# GD32F20x_CL register map
File version: 1.0
CPU: CM3 r2p1, little endian, no MPU, no FPU, 4 interrupt priority bits
Registers are 32-bit, read-write, reset 0x0 unless marked. A register's access mark holds for its fields unless they carry their own. Offsets are from the block's base; [hi:lo] are bit positions; {n}, {i} and the like mark numbered series.

## CAU — Cryptographic acceleration unit
Base 0x50060000
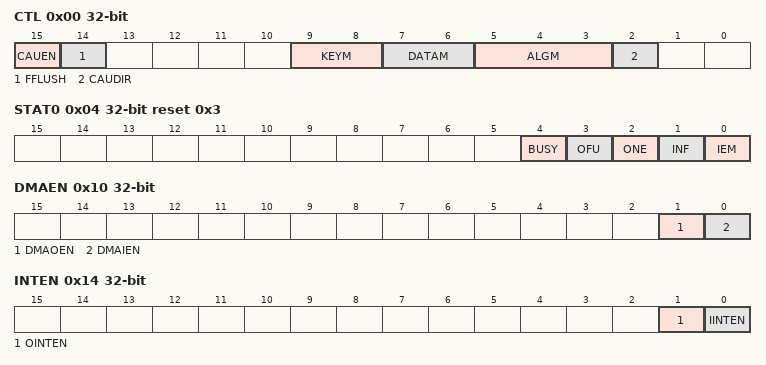
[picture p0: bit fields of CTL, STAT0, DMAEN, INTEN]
0x00 CTL access per field — CAU control register
  [15] CAUEN rw — Cryptographic module enable
  [14] FFLUSH wo — FIFO flush
  [9:8] KEYM rw — AES key size mode configuration
  [7:6] DATAM rw — Data swapping type mode configuration
  [5:3] ALGM rw — Encryption/decryption algorithm mode
  [2] CAUDIR rw — CAU direction
0x04 STAT0 ro reset 0x3 — CAU status register 0
  [4] BUSY — BUSY flag
  [3] OFU — OUT FIFO full flag
  [2] ONE — OUT FIFO not empty flag
  [1] INF — IN FIFO not full flag
  [0] IEM — IN FIFO empty flag
0x08 DI — CAU data input register
  [31:0] DI — Data input
0x0C DO ro — CAU data output register
  [31:0] DO — Data output
0x10 DMAEN — CAU DMA enable register
  [1] DMAOEN — Out FIFO DMA enable
  [0] DMAIEN — In FIFO DMA enable
0x14 INTEN — CAU interrupt enable register
  [1] OINTEN — Out FIFO interrupt enable
  [0] IINTEN — In FIFO interrupt enable
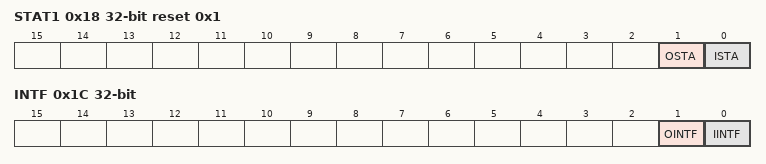
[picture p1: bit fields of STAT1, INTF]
0x18 STAT1 ro reset 0x1 — CAU interrupt status flag register 1
  [1] OSTA — Out FIFO interrupt flag
  [0] ISTA — In FIFO interrupt flag
0x1C INTF ro — CAU enable interrupt status flag register
  [1] OINTF — Out FIFO enabled interrupt flag
  [0] IINTF — In FIFO enabled interrupt flag
{0x20+8i} KEY{i}H wo (i=0..3) — CAU key register
  [31:0] KEY{i}H — Key for DES,TDES,AES
{0x24+8i} KEY{i}L wo (i=0..3) — CAU key register
  [31:0] KEY{i}L — Key for DES,TDES,AES
0x40 IV0H — CAU initialization register
  [31:0] IV0H — The initialization vector for DES,TDES,AES
0x44 IV0L — CAU initialization register
  [31:0] IV0L — The initialization vector for DES,TDES,AES
0x48 IV1H — CAU initialization register
  [31:0] IV1H — The initialization vector for DES,TDES,AES
0x4C IV1L — CAU initialization register
  [31:0] IV1L — The initialization vector for DES,TDES,AES

## CRC — CRC calculation unit
Base 0x40023000
0x00 DATA reset 0xFFFFFFFF
  [31:0] DATA — CRC calculation result bits
0x04 FDATA — Independent Data register
  [7:0] FDATA — Free Data Register bits
0x08 CTL wo — Control register
  [0] RST — Reset bit

## DAC — Digital to analog converter
Base 0x40007400
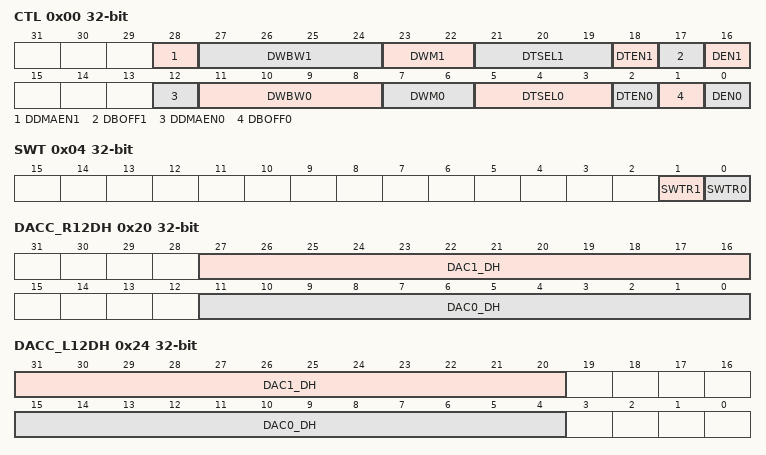
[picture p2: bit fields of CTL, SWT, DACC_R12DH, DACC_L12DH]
0x00 CTL — control register
  [28] DDMAEN1 — DAC1 DMA enable
  [27:24] DWBW1 — DAC1 noise wave bit width
  [23:22] DWM1 — DAC1 noise wave mode
  [21:19] DTSEL1 — DAC1 trigger selection
  [18] DTEN1 — DAC1 trigger enable
  [17] DBOFF1 — DAC1 output buffer turn off
  [16] DEN1 — DAC1 enable
  [12] DDMAEN0 — DAC0 DMA enable
  [11:8] DWBW0 — DAC0 noise wave bit width
  [7:6] DWM0 — DAC0 noise wave mode
  [5:3] DTSEL0 — DAC0 trigger selection
  [2] DTEN0 — DAC0 trigger enable
  [1] DBOFF0 — DAC0 output buffer turn off
  [0] DEN0 — DAC0 enable
0x04 SWT wo — software trigger register
  [1] SWTR1 — DAC1 software trigger
  [0] SWTR0 — DAC0 software trigger
0x08 DAC0_R12DH — DAC0 12-bit right-aligned data holding register
  [11:0] DAC0_DH — DAC0 12-bit right-aligned data
0x0C DAC0_L12DH — DAC0 12-bit left-aligned data holding register
  [15:4] DAC0_DH — DAC0 12-bit left-aligned data
0x10 DAC0_R8DH — DAC0 8-bit right aligned data holding register
  [7:0] DAC0_DH — DAC0 8-bit right-aligned data
0x14 DAC1_R12DH — DAC1 12-bit right-aligned data holding register
  [11:0] DAC1_DH — DAC1 12-bit right-aligned data
0x18 DAC1_L12DH — DAC1 12-bit left aligned data holding register
  [15:4] DAC1_DH — DAC1 12-bit left-aligned data
0x1C DAC1_R8DH — DAC1 8-bit right aligned data holding register
  [7:0] DAC1_DH — DAC1 8-bit right-aligned data
0x20 DACC_R12DH — DAC concurrent mode 12-bit right-aligned data holding register
  [27:16] DAC1_DH — DAC1 12-bit right-aligned data
  [11:0] DAC0_DH — DAC0 12-bit right-aligned data
0x24 DACC_L12DH — DAC concurrent mode 12-bit left aligned data holding register
  [31:20] DAC1_DH — DAC1 12-bit left-aligned data
  [15:4] DAC0_DH — DAC0 12-bit left-aligned data
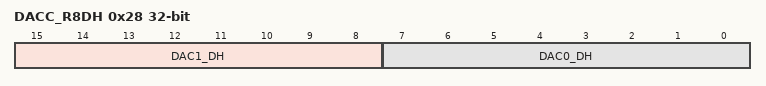
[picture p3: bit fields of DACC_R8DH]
0x28 DACC_R8DH — DAC concurrent mode 8-bit right aligned data holding register
  [15:8] DAC1_DH — DAC1 8-bit right-aligned data
  [7:0] DAC0_DH — DAC0 8-bit right-aligned data
0x2C DAC0_DO ro — DAC0 data output register
  [11:0] DAC0_DO — DAC0 data output
0x30 DAC1_DO ro — DAC1 data output register
  [11:0] DAC1_DO — DAC1 data output
